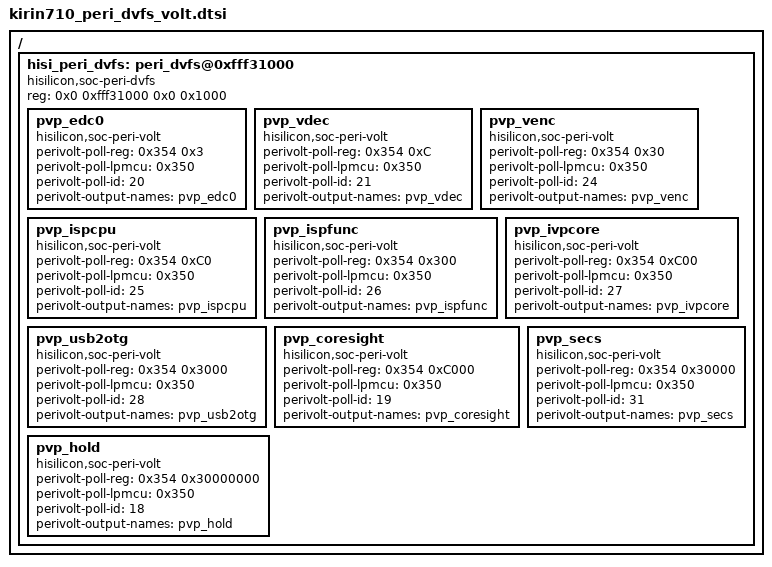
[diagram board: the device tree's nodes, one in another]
/*
 * Hisilicon Ltd. Hi3650 SoC
 *
 * Copyright (C) 2012-2013 Hisilicon Ltd.
 *
 * This program is free software; you can redistribute it and/or modify
 * it under the terms of the GNU General Public License version 2 as
 * publishhed by the Free Software Foundation.
 */

/{
			hisi_peri_dvfs: peri_dvfs@0xfff31000 {
				compatible = "hisilicon,soc-peri-dvfs";
				reg = <0x0 0xfff31000 0x0 0x1000>;
				status = "ok";

				pvp_edc0: pvp_edc0 {
					compatible = "hisilicon,soc-peri-volt";
					perivolt-poll-reg = <0x354 0x3>;
					perivolt-poll-lpmcu = <0x350>;
					perivolt-poll-id = <20>;
					perivolt-output-names = "pvp_edc0";
				};

				pvp_vdec: pvp_vdec {
					compatible = "hisilicon,soc-peri-volt";
					perivolt-poll-reg = <0x354 0xC>;
					perivolt-poll-lpmcu = <0x350>;
					perivolt-poll-id = <21>;
					perivolt-output-names = "pvp_vdec";
				};

				pvp_venc: pvp_venc {
					compatible = "hisilicon,soc-peri-volt";
					perivolt-poll-reg = <0x354 0x30>;
					perivolt-poll-lpmcu = <0x350>;
					perivolt-poll-id = <24>;
					perivolt-output-names = "pvp_venc";
				};

				pvp_ispcpu: pvp_ispcpu {
					compatible = "hisilicon,soc-peri-volt";
					perivolt-poll-reg = <0x354 0xC0>;
					perivolt-poll-lpmcu = <0x350>;
					perivolt-poll-id = <25>;
					perivolt-output-names = "pvp_ispcpu";
				};

				pvp_ispfunc: pvp_ispfunc {
					compatible = "hisilicon,soc-peri-volt";
					perivolt-poll-reg = <0x354 0x300>;
					perivolt-poll-lpmcu = <0x350>;
					perivolt-poll-id = <26>;
					perivolt-output-names = "pvp_ispfunc";
				};

				pvp_ivpcore: pvp_ivpcore {
					compatible = "hisilicon,soc-peri-volt";
					perivolt-poll-reg = <0x354 0xC00>;
					perivolt-poll-lpmcu = <0x350>;
					perivolt-poll-id = <27>;
					perivolt-output-names = "pvp_ivpcore";
				};

				pvp_usb2otg: pvp_usb2otg {
					compatible = "hisilicon,soc-peri-volt";
					perivolt-poll-reg = <0x354 0x3000>;
					perivolt-poll-lpmcu = <0x350>;
					perivolt-poll-id = <28>;
					perivolt-output-names = "pvp_usb2otg";
				};

				pvp_coresight: pvp_coresight {
					compatible = "hisilicon,soc-peri-volt";
					perivolt-poll-reg = <0x354 0xC000>;
					perivolt-poll-lpmcu = <0x350>;
					perivolt-poll-id = <19>;
					perivolt-output-names = "pvp_coresight";
				};

				pvp_secs: pvp_secs {
					compatible = "hisilicon,soc-peri-volt";
					perivolt-poll-reg = <0x354 0x30000>;
					perivolt-poll-lpmcu = <0x350>;
					perivolt-poll-id = <31>;
					perivolt-output-names = "pvp_secs";
				};

				pvp_hold: pvp_hold {
					compatible = "hisilicon,soc-peri-volt";
					perivolt-poll-reg = <0x354 0x30000000>;
					perivolt-poll-lpmcu = <0x350>;
					perivolt-poll-id = <18>;
					perivolt-output-names = "pvp_hold";
				};
			};
};
